# BlueNRG2 register map
Vendor: STMicroelectronics; Series: BlueNRG1; File version: 1.0.0
CPU: CM0 r0p0, little endian, no MPU, no FPU, 2 interrupt priority bits
Registers are 32-bit, read-write, reset 0x0 unless marked. A register's access mark holds for its fields unless they carry their own. Offsets are from the block's base; [hi:lo] are bit positions; 'fields as' and 'values as' point back to an identical list.

## MFT1
Base 0x40D00000
Same registers: MFT2 0x40E00000
0x00 TNCNT1 16-bit — Timer / Counter1 register
0x04 TNCRA 16-bit — Capture / Reload A register
0x08 TNCRB 16-bit — Capture / Reload B register
0x0C TNCNT2 16-bit — Timer / Counter2 register
0x10 TNPRSC 8-bit — Clock prescaler register
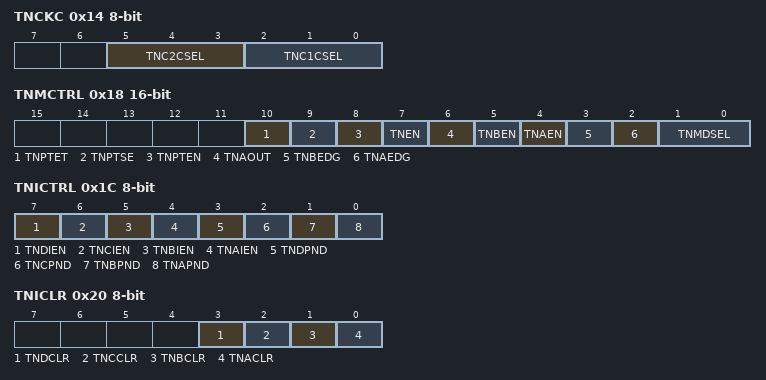
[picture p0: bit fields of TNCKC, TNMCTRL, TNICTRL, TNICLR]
0x14 TNCKC 8-bit — Clock unit control register
  [5:3] TNC2CSEL — Define the clock mode for timer/counter 2:<ul><li>000b: No clock (Timer/Counter 1 stopped).</li><li>001b: Prescaled system clock.</li><li>010b: External event on TnB (mode 1 and 3 only).</li><li>011b: Pulse accumulate (mode 1 and 3 only).</li><li>100b: Low-speed clock.</li></ul>
    0=NO_CLOCK (No clock (Timer/Counter 1 stopped)); 1=PRESCALED (Prescaled system clock pclk); 2=EXTERNAL_EVENT (External event on TnB); 3=PULSE_ACCUMULATE; 4=LOW_SPEED_CLOCK (Low-speed clock slow_clk_c)
  [2:0] TNC1CSEL — Define the clock mode for timer/counter 1:<ul><li>000b: No clock (Timer/Counter 1 stopped).</li><li>001b: Prescaled system clock.</li><li>010b: External event on TnB (mode 1 and 3 only).</li><li>011b: Pulse accumulate (mode 1 and 3 only).</li><li>100b: Low-speed clock.</li></ul>
    values as TNC2CSEL
0x18 TNMCTRL 16-bit — Timer mode control register
  [10] TNPTET — Tn pulse-train event trigger:<ul><li>0: No pulse-train event trigger occurred.</li><li>1: Pulse-train event trigger occurred (in mode 1a).</li></ul>
  [9] TNPTSE — Tn pulse-train sofware trigger enable:<ul><li>0: No effect.</li><li>1: Pulse-train generation trigger (in mode 1a)</li></ul>
  [8] TNPTEN — Tn pulse-train mode enable:<ul><li>0: Mode 1a not selected.</li><li>1: Mode 1a selected (if TnMDSEL = 00).</li></ul>
  [7] TNEN — MFTX enable:<ul><li>0: MFTX disable.</li><li>1: MFTX enable.</li></ul>
    0=MFTX_DISABLE; 1=MFTX_ENABLE
  [6] TNAOUT — TnA output data:<ul><li>0: Pin is low.</li><li>1: Pin is high.</li></ul>
    0=LOW (Pin is low); 1=HIGH (Pin is high)
  [5] TNBEN — TnB enable:<ul><li>0: TnB in disable.</li><li>1: TnB in enable.</li></ul>
    0=TNB_IN_DISABLE; 1=TNB_IN_ENABLE
  [4] TNAEN — TnA enable:<ul><li>0: TnA in disable.</li><li>1: TnA in enable.</li></ul>
    0=TNA_IN_DISABLE; 1=TNA_IN_ENABLE
  [3] TNBEDG — TnB edge polarity:<ul><li>0: Input is sensitive to falling edges.</li><li>1: Input is sensitive to rising edges.</li></ul>
    0=FALLING_EDGE (Input is sensitive to falling edges); 1=RISING_EDGE (Input is sensitive to rising edges)
  [2] TNAEDG — TnA edge polarity:<ul><li>0: Input is sensitive to falling edges.</li><li>1: Input is sensitive to rising edges.</li></ul>
    values as TNBEDG
  [1:0] TNMDSEL — MFTX mode select:<ul><li>00b: Mode 1 or 1a: PWM mode and system timer or pulse train.</li><li>01b: Mode 2: Dual-input capture and system timer.</li><li>10b: Mode 3: Dual independent timer/counter.</li><li>11b: Mode 4: Single timer and single input capture.</li></ul>
    0=PWM (PWM mode and system timer or pulse train); 1=DUAL_INPUT_CAPTURE (Dual-input capture and system timer); 2=DUAL_INDEPENDENT (Dual independent timer/counter); 3=SINGLE (Single timer and single input capture)
0x1C TNICTRL 8-bit — Timer interrupt control register
  [7] TNDIEN — Timer interrupt D enable:<ul><li>0: Interrupt disabled.</li><li>1: Interrupt enabled.</li></ul>
  [6] TNCIEN — Timer interrupt C enable:<ul><li>0: Interrupt disabled.</li><li>1: Interrupt enabled.</li></ul>
  [5] TNBIEN — Timer interrupt B enable:<ul><li>0: Interrupt disabled.</li><li>1: Interrupt enabled.</li></ul>
  [4] TNAIEN — Timer interrupt A enable:<ul><li>0: Interrupt disabled.</li><li>1: Interrupt enabled.</li></ul>
  [3] TNDPND ro — Timer interrupt D pending:<ul><li>0: No interrupt source pending.</li><li>1: Interrupt source pending.</li></ul>
  [2] TNCPND ro — Timer interrupt C pending:<ul><li>0: No interrupt source pending.</li><li>1: Interrupt source pending.</li></ul>
  [1] TNBPND ro — Timer interrupt B pending:<ul><li>0: No interrupt source pending.</li><li>1: Interrupt source pending.</li></ul>
  [0] TNAPND ro — Timer interrupt A pending:<ul><li>0: No interrupt source pending.</li><li>1: Interrupt source pending.</li></ul>
0x20 TNICLR 8-bit wo — Timer interrupt clear register
  [3] TNDCLR — 1: clear the timer pending flag D.
  [2] TNCCLR — 1: clear the timer pending flag C.
  [1] TNBCLR — 1: clear the timer pending flag B.
  [0] TNACLR — 1: clear the timer pending flag A.
